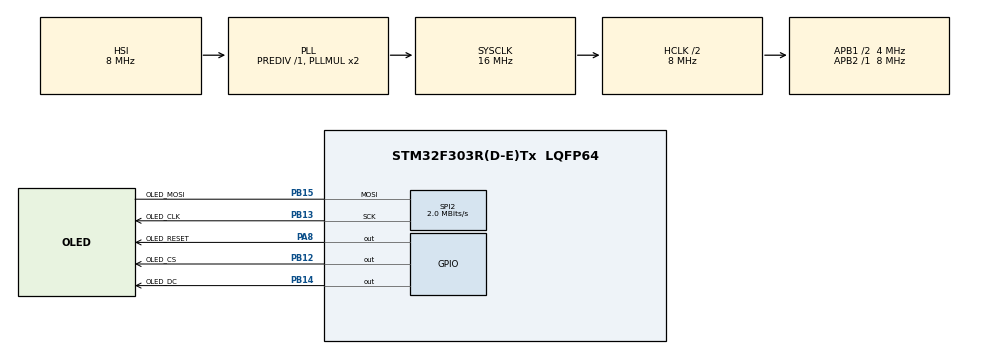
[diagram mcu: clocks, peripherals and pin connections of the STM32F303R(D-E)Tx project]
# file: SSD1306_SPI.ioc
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Mcu.Family=STM32F3
Mcu.Name=STM32F303R(D-E)Tx
Mcu.Package=LQFP64
NVIC.PriorityGroup=NVIC_PRIORITYGROUP_4
PA13.Mode=Serial_Wire
PA13.Signal=SYS_JTMS-SWDIO
PA14.Mode=Serial_Wire
PA14.Signal=SYS_JTCK-SWCLK
PA8.GPIO_Label=OLED_RESET
PA8.Signal=GPIO_Output
PB12.GPIO_Label=OLED_CS
PB12.Signal=GPIO_Output
PB13.GPIO_Label=OLED_CLK
PB13.Mode=Simplex_Bidirectional_Master
PB13.Signal=SPI2_SCK
PB14.GPIO_Label=OLED_DC
PB14.Signal=GPIO_Output
PB15.GPIO_Label=OLED_MOSI
PB15.Mode=Simplex_Bidirectional_Master
PB15.Signal=SPI2_MOSI
ProjectManager.HeapSize=0x200
ProjectManager.StackSize=0x400
ProjectManager.TargetToolchain=SW4STM32
RCC.AHBCLKDivider=RCC_SYSCLK_DIV2
RCC.AHBFreq_Value=8000000
RCC.APB1CLKDivider=RCC_HCLK_DIV2
RCC.APB1Freq_Value=4000000
RCC.APB1TimFreq_Value=8000000
RCC.APB2Freq_Value=8000000
RCC.APB2TimFreq_Value=8000000
RCC.CortexFreq_Value=8000000
RCC.HCLKFreq_Value=8000000
RCC.HSE_VALUE=8000000
RCC.HSI_VALUE=8000000
RCC.LSE_VALUE=32768
RCC.SYSCLKFreq_VALUE=16000000
RCC.SYSCLKSourceVirtual=RCC_SYSCLKSOURCE_PLLCLK
RCC.USBFreq_Value=16000000
SPI2.CalculateBaudRate=2.0 MBits/s
SPI2.DataSize=SPI_DATASIZE_8BIT
SPI2.Direction=SPI_DIRECTION_1LINE
SPI2.Mode=SPI_MODE_MASTER
SPI2.VirtualType=VM_MASTER
board=custom

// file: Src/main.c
/* USER CODE BEGIN Header */
/**
  ******************************************************************************
  * @file           : main.c
  * @brief          : Main program body
  ******************************************************************************
  * @attention
  *
  * <h2><center>&copy; Copyright (c) 2020 STMicroelectronics.
  * All rights reserved.</center></h2>
  *
  * This software component is licensed by ST under BSD 3-Clause license,
  * the "License"; You may not use this file except in compliance with the
  * License. You may obtain a copy of the License at:
  *                        opensource.org/licenses/BSD-3-Clause
  *
  ******************************************************************************
  */
/* USER CODE END Header */

#include "main.h"
#include "ssd1306.h"
#include "ssd1306_fonts.h"
#include "ssd1306_tests.h"

SPI_HandleTypeDef hspi2;

void SystemClock_Config(void);
static void MX_GPIO_Init(void);
static void MX_SPI2_Init(void);

int main(void)
{

  /* MCU Configuration--------------------------------------------------------*/

  /* Reset of all peripherals, Initializes the Flash interface and the Systick. */
  HAL_Init();

  /* Configure the system clock */
  SystemClock_Config();

  /* Initialize all configured peripherals */
  MX_GPIO_Init();
  MX_SPI2_Init();
  /* USER CODE BEGIN 2 */

  ssd1306_Init();
  //ssd1306_TestAll();
  ssd1306_Fill(White);

  ssd1306_UpdateScreen();
  /* USER CODE END 2 */

  /* Infinite loop */
  while (1)
  {

  }
}

void SystemClock_Config(void)
{
  RCC_OscInitTypeDef RCC_OscInitStruct = {0};
  RCC_ClkInitTypeDef RCC_ClkInitStruct = {0};

  /** Initializes the CPU, AHB and APB busses clocks
  */
  RCC_OscInitStruct.OscillatorType = RCC_OSCILLATORTYPE_HSI;
  RCC_OscInitStruct.HSIState = RCC_HSI_ON;
  RCC_OscInitStruct.HSICalibrationValue = RCC_HSICALIBRATION_DEFAULT;
  RCC_OscInitStruct.PLL.PLLState = RCC_PLL_ON;
  RCC_OscInitStruct.PLL.PLLSource = RCC_PLLSOURCE_HSI;
  RCC_OscInitStruct.PLL.PLLMUL = RCC_PLL_MUL2;
  RCC_OscInitStruct.PLL.PREDIV = RCC_PREDIV_DIV1;
  if (HAL_RCC_OscConfig(&RCC_OscInitStruct) != HAL_OK)
  {
    Error_Handler();
  }
  /** Initializes the CPU, AHB and APB busses clocks
  */
  RCC_ClkInitStruct.ClockType = RCC_CLOCKTYPE_HCLK|RCC_CLOCKTYPE_SYSCLK
                              |RCC_CLOCKTYPE_PCLK1|RCC_CLOCKTYPE_PCLK2;
  RCC_ClkInitStruct.SYSCLKSource = RCC_SYSCLKSOURCE_PLLCLK;
  RCC_ClkInitStruct.AHBCLKDivider = RCC_SYSCLK_DIV2;
  RCC_ClkInitStruct.APB1CLKDivider = RCC_HCLK_DIV2;
  RCC_ClkInitStruct.APB2CLKDivider = RCC_HCLK_DIV1;

  if (HAL_RCC_ClockConfig(&RCC_ClkInitStruct, FLASH_LATENCY_0) != HAL_OK)
  {
    Error_Handler();
  }
}

static void MX_SPI2_Init(void)
{

  /* SPI2 parameter configuration*/
  hspi2.Instance = SPI2;
  hspi2.Init.Mode = SPI_MODE_MASTER;
  hspi2.Init.Direction = SPI_DIRECTION_1LINE;
  hspi2.Init.DataSize = SPI_DATASIZE_8BIT;
  hspi2.Init.CLKPolarity = SPI_POLARITY_LOW;
  hspi2.Init.CLKPhase = SPI_PHASE_1EDGE;
  hspi2.Init.NSS = SPI_NSS_SOFT;
  hspi2.Init.BaudRatePrescaler = SPI_BAUDRATEPRESCALER_2;
  hspi2.Init.FirstBit = SPI_FIRSTBIT_MSB;
  hspi2.Init.TIMode = SPI_TIMODE_DISABLE;
  hspi2.Init.CRCCalculation = SPI_CRCCALCULATION_DISABLE;
  hspi2.Init.CRCPolynomial = 7;
  hspi2.Init.CRCLength = SPI_CRC_LENGTH_DATASIZE;
  hspi2.Init.NSSPMode = SPI_NSS_PULSE_ENABLE;
  if (HAL_SPI_Init(&hspi2) != HAL_OK)
  {
    Error_Handler();
  }

}

static void MX_GPIO_Init(void)
{
  GPIO_InitTypeDef GPIO_InitStruct = {0};

  /* GPIO Ports Clock Enable */
  __HAL_RCC_GPIOB_CLK_ENABLE();
  __HAL_RCC_GPIOA_CLK_ENABLE();

  /*Configure GPIO pin Output Level */
  HAL_GPIO_WritePin(GPIOB, OLED_CS_Pin|OLED_DC_Pin, GPIO_PIN_RESET);

  /*Configure GPIO pin Output Level */
  HAL_GPIO_WritePin(OLED_RESET_GPIO_Port, OLED_RESET_Pin, GPIO_PIN_RESET);

  /*Configure GPIO pins : OLED_CS_Pin OLED_DC_Pin */
  GPIO_InitStruct.Pin = OLED_CS_Pin|OLED_DC_Pin;
  GPIO_InitStruct.Mode = GPIO_MODE_OUTPUT_PP;
  GPIO_InitStruct.Pull = GPIO_NOPULL;
  GPIO_InitStruct.Speed = GPIO_SPEED_FREQ_LOW;
  HAL_GPIO_Init(GPIOB, &GPIO_InitStruct);

  /*Configure GPIO pin : OLED_RESET_Pin */
  GPIO_InitStruct.Pin = OLED_RESET_Pin;
  GPIO_InitStruct.Mode = GPIO_MODE_OUTPUT_PP;
  GPIO_InitStruct.Pull = GPIO_NOPULL;
  GPIO_InitStruct.Speed = GPIO_SPEED_FREQ_LOW;
  HAL_GPIO_Init(OLED_RESET_GPIO_Port, &GPIO_InitStruct);

}

void Error_Handler(void)
{
}

/************************ (C) COPYRIGHT STMicroelectronics *****END OF FILE****/
